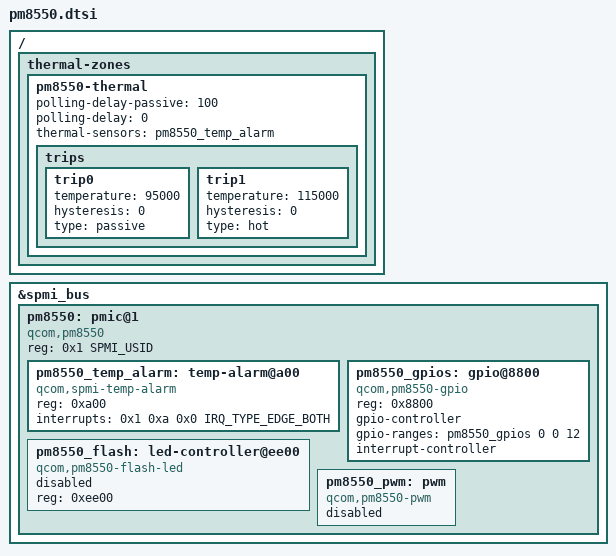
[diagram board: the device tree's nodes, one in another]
// SPDX-License-Identifier: BSD-3-Clause
/*
 * Copyright (c) 2022, Linaro Limited
 */

#include <dt-bindings/interrupt-controller/irq.h>
#include <dt-bindings/spmi/spmi.h>

/ {
	thermal-zones {
		pm8550-thermal {
			polling-delay-passive = <100>;
			polling-delay = <0>;

			thermal-sensors = <&pm8550_temp_alarm>;

			trips {
				trip0 {
					temperature = <95000>;
					hysteresis = <0>;
					type = "passive";
				};

				trip1 {
					temperature = <115000>;
					hysteresis = <0>;
					type = "hot";
				};
			};
		};
	};
};


&spmi_bus {
	pm8550: pmic@1 {
		compatible = "qcom,pm8550", "qcom,spmi-pmic";
		reg = <0x1 SPMI_USID>;
		#address-cells = <1>;
		#size-cells = <0>;

		pm8550_temp_alarm: temp-alarm@a00 {
			compatible = "qcom,spmi-temp-alarm";
			reg = <0xa00>;
			interrupts = <0x1 0xa 0x0 IRQ_TYPE_EDGE_BOTH>;
			#thermal-sensor-cells = <0>;
		};

		pm8550_gpios: gpio@8800 {
			compatible = "qcom,pm8550-gpio", "qcom,spmi-gpio";
			reg = <0x8800>;
			gpio-controller;
			gpio-ranges = <&pm8550_gpios 0 0 12>;
			#gpio-cells = <2>;
			interrupt-controller;
			#interrupt-cells = <2>;
		};

		pm8550_flash: led-controller@ee00 {
			compatible = "qcom,pm8550-flash-led", "qcom,spmi-flash-led";
			reg = <0xee00>;
			status = "disabled";
		};

		pm8550_pwm: pwm {
			compatible = "qcom,pm8550-pwm", "qcom,pm8350c-pwm";

			#address-cells = <1>;
			#size-cells = <0>;
			#pwm-cells = <2>;

			status = "disabled";
		};
	};
};
